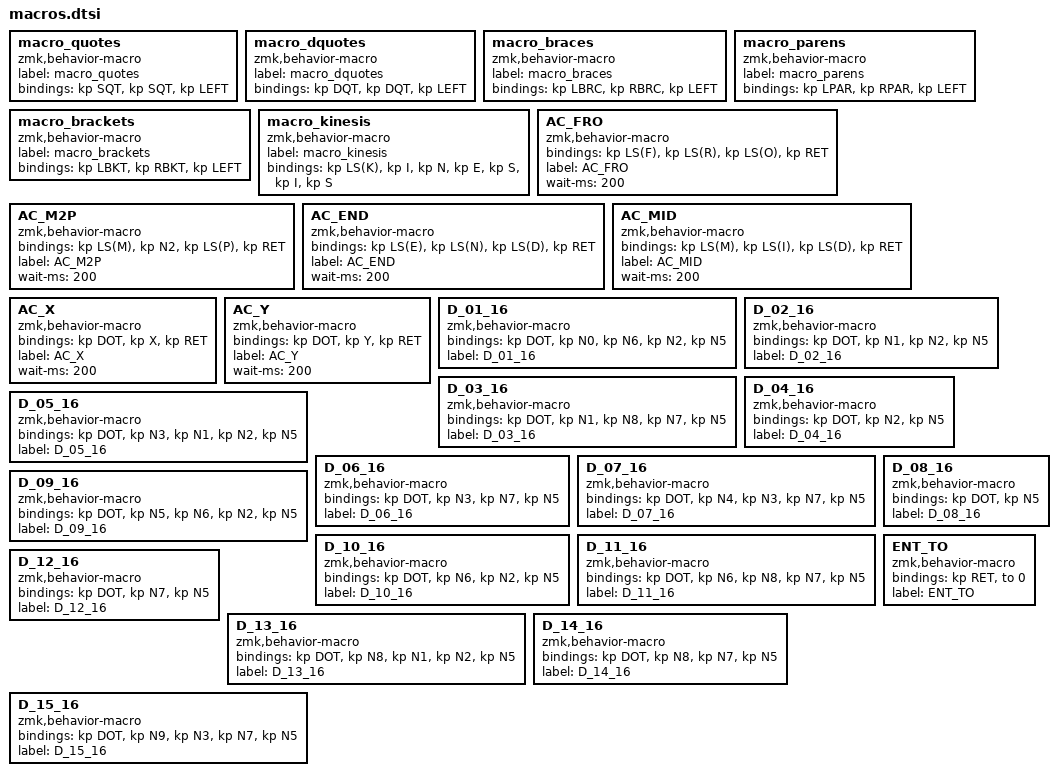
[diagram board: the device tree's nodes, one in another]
  macro_quotes: macro_quotes {
    compatible = "zmk,behavior-macro";
    label = "macro_quotes";
    #binding-cells = <0>;
    bindings = <&kp SQT>, <&kp SQT>, <&kp LEFT>;
  };
  macro_dquotes: macro_dquotes {
    compatible = "zmk,behavior-macro";
    label = "macro_dquotes";
    #binding-cells = <0>;
    bindings = <&kp DQT>, <&kp DQT>, <&kp LEFT>;
  };
  macro_braces: macro_braces {
    compatible = "zmk,behavior-macro";
    label = "macro_braces";
    #binding-cells = <0>;
    bindings = <&kp LBRC>, <&kp RBRC>, <&kp LEFT>;
  };
  macro_parens: macro_parens {
    compatible = "zmk,behavior-macro";
    label = "macro_parens";
    #binding-cells = <0>;
    bindings = <&kp LPAR>, <&kp RPAR>, <&kp LEFT>;
  };
  macro_brackets: macro_brackets {
    compatible = "zmk,behavior-macro";
    label = "macro_brackets";
    #binding-cells = <0>;
    bindings = <&kp LBKT>, <&kp RBKT>, <&kp LEFT>;
  };
  macro_kinesis: macro_kinesis {
    compatible = "zmk,behavior-macro";
    label = "macro_kinesis";
    #binding-cells = <0>;
    bindings = <&kp LS(K)>, <&kp I>, <&kp N>, <&kp E>, <&kp S>, <&kp I>, <&kp S>;
  };

  AC_FRO: AC_FRO {
              compatible = "zmk,behavior-macro";
              #binding-cells = <0>;
              bindings = <&kp LS(F) &kp LS(R) &kp LS(O) &kp RET>;
              label = "AC_FRO";
              wait-ms = <200>;
  };
  
  AC_M2P: AC_M2P {
      compatible = "zmk,behavior-macro";
      #binding-cells = <0>;
      bindings = <&kp LS(M) &kp N2 &kp LS(P) &kp RET>;
      label = "AC_M2P";
      wait-ms = <200>;
  };
  
  AC_END: AC_END {
      compatible = "zmk,behavior-macro";
      #binding-cells = <0>;
      bindings = <&kp LS(E) &kp LS(N) &kp LS(D) &kp RET>;
      label = "AC_END";
      wait-ms = <200>;
  };
  
  AC_MID: AC_MID {
      compatible = "zmk,behavior-macro";
      #binding-cells = <0>;
      bindings = <&kp LS(M) &kp LS(I) &kp LS(D) &kp RET>;
      label = "AC_MID";
      wait-ms = <200>;
  };

  AC_X: AC_X {
      compatible = "zmk,behavior-macro";
      #binding-cells = <0>;
      bindings = <&kp DOT &kp X &kp RET>;
      label = "AC_X";
      wait-ms = <200>;
  };

  AC_Y: AC_Y {
      compatible = "zmk,behavior-macro";
      #binding-cells = <0>;
      bindings = <&kp DOT &kp Y &kp RET>;
      label = "AC_Y";
      wait-ms = <200>;
  };
  
  D_01_16: D_01_16 {
      compatible = "zmk,behavior-macro";
      #binding-cells = <0>;
      bindings = <&kp DOT &kp N0 &kp N6 &kp N2 &kp N5>;
      label = "D_01_16";
  };
  
  D_02_16: D_02_16 {
      compatible = "zmk,behavior-macro";
      #binding-cells = <0>;
      bindings = <&kp DOT &kp N1 &kp N2 &kp N5>;
      label = "D_02_16";
  };
  
  D_03_16: D_03_16 {
      compatible = "zmk,behavior-macro";
      #binding-cells = <0>;
      bindings = <&kp DOT &kp N1 &kp N8 &kp N7 &kp N5>;
      label = "D_03_16";
  };
  
  D_04_16: D_04_16 {
      compatible = "zmk,behavior-macro";
      #binding-cells = <0>;
      bindings = <&kp DOT &kp N2 &kp N5>;
      label = "D_04_16";
  };
  
  D_05_16: D_05_16 {
      compatible = "zmk,behavior-macro";
      #binding-cells = <0>;
      bindings = <&kp DOT &kp N3 &kp N1 &kp N2 &kp N5>;
      label = "D_05_16";
  };
  
  D_06_16: D_06_16 {
      compatible = "zmk,behavior-macro";
      #binding-cells = <0>;
      bindings = <&kp DOT &kp N3 &kp N7 &kp N5>;
      label = "D_06_16";
  };
  
  D_07_16: D_07_16 {
      compatible = "zmk,behavior-macro";
      #binding-cells = <0>;
      bindings = <&kp DOT &kp N4 &kp N3 &kp N7 &kp N5>;
      label = "D_07_16";
  };
  
  D_08_16: D_08_16 {
      compatible = "zmk,behavior-macro";
      #binding-cells = <0>;
      bindings = <&kp DOT &kp N5>;
      label = "D_08_16";
  };
  
  D_09_16: D_09_16 {
      compatible = "zmk,behavior-macro";
      #binding-cells = <0>;
      bindings = <&kp DOT &kp N5 &kp N6 &kp N2 &kp N5>;
      label = "D_09_16";
  };
  
  D_10_16: D_10_16 {
      compatible = "zmk,behavior-macro";
      #binding-cells = <0>;
      bindings = <&kp DOT &kp N6 &kp N2 &kp N5>;
      label = "D_10_16";
  };
  
  D_11_16: D_11_16 {
      compatible = "zmk,behavior-macro";
      #binding-cells = <0>;
      bindings = <&kp DOT &kp N6 &kp N8 &kp N7 &kp N5>;
      label = "D_11_16";
  };
  
  D_12_16: D_12_16 {
      compatible = "zmk,behavior-macro";
      #binding-cells = <0>;
      bindings = <&kp DOT &kp N7 &kp N5>;
      label = "D_12_16";
  };
  
  D_13_16: D_13_16 {
      compatible = "zmk,behavior-macro";
      #binding-cells = <0>;
      bindings = <&kp DOT &kp N8 &kp N1 &kp N2 &kp N5>;
      label = "D_13_16";
  };
  
  D_14_16: D_14_16 {
      compatible = "zmk,behavior-macro";
      #binding-cells = <0>;
      bindings = <&kp DOT &kp N8 &kp N7 &kp N5>;
      label = "D_14_16";
  };
  
  D_15_16: D_15_16 {
      compatible = "zmk,behavior-macro";
      #binding-cells = <0>;
      bindings = <&kp DOT &kp N9 &kp N3 &kp N7 &kp N5>;
      label = "D_15_16";
  };

  ENT_TO: ENT_TO {
      compatible = "zmk,behavior-macro";
      #binding-cells = <0>;
      bindings = <&kp RET &to 0>;
      label = "ENT_TO";
  };

